AUTOSAR XML (schema 4-0-3)
standard types defined: Boolean, UInt32
package /AUTOSAR_Platform/DataConstrs
  range DC_Boolean: raw 0..1
package /PATAC/Facility/DataTypes/Implementation
  compu method COMPU_Boolean: 0=FALSE, 1=TRUE
  unit NoUnit: factor-si-to-unit=1, offset-si-to-unit=0
package /PATAC/MSM/ComponentTypes
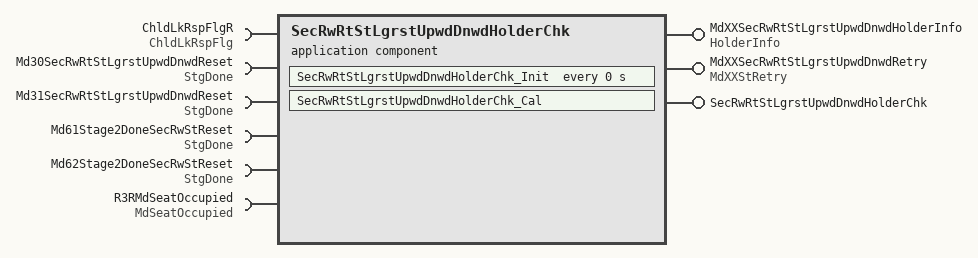
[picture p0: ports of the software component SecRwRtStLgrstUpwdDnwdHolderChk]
  application sw component type SecRwRtStLgrstUpwdDnwdHolderChk
    provide port MdXXSecRwRtStLgrstUpwdDnwdHolderInfo: nonqueued-sender-com-spec{data-element=HolderInfo/Val, init-value=0}, provided-interface=HolderInfo
    provide port MdXXSecRwRtStLgrstUpwdDnwdRetry: nonqueued-sender-com-spec{data-element=MdXXStRetry/Val, init-value=0}, provided-interface=MdXXStRetry
    provide port SecRwRtStLgrstUpwdDnwdHolderChk: server-com-spec{operation=Cal, queue-length=1}, provided-interface=SecRwRtStLgrstUpwdDnwdHolderChk
    6 x require port:
      ChldLkRspFlgR: nonqueued-receiver-com-spec{data-element=ChldLkRspFlg/Val, filter=data-filter-type=ALWAYS, init-value=0}, required-interface=ChldLkRspFlg
      Md30SecRwRtStLgrstUpwdDnwdReset: nonqueued-receiver-com-spec{data-element=StgDone/Val, filter=data-filter-type=ALWAYS, init-value=0}, required-interface=StgDone
      Md31SecRwRtStLgrstUpwdDnwdReset: nonqueued-receiver-com-spec{data-element=StgDone/Val, filter=data-filter-type=ALWAYS, init-value=0}, required-interface=StgDone
      Md61Stage2DoneSecRwStReset: nonqueued-receiver-com-spec{data-element=StgDone/Val, filter=data-filter-type=ALWAYS, init-value=0}, required-interface=StgDone
      Md62Stage2DoneSecRwStReset: nonqueued-receiver-com-spec{data-element=StgDone/Val, filter=data-filter-type=ALWAYS, init-value=0}, required-interface=StgDone
      R3RMdSeatOccupied: nonqueued-receiver-com-spec{data-element=MdSeatOccupied/Val, filter=data-filter-type=ALWAYS, init-value=0}, required-interface=MdSeatOccupied
    behavior SecRwRtStLgrstUpwdDnwdHolderChk_InternalBehavior
      operation invoked event OIT_SecRwRtStLgrstUpwdDnwdHolderChk_Cal_SecRwRtStLgrstUpwdDnwdHolderChk_Cal: start-on-event=SecRwRtStLgrstUpwdDnwdHolderChk_Cal, operation=SecRwRtStLgrstUpwdDnwdHolderChk.Cal
      timing event SecRwRtStLgrstUpwdDnwdHolderChk_InitEvent: start-on-event=SecRwRtStLgrstUpwdDnwdHolderChk_Init, period=0
      runnable SecRwRtStLgrstUpwdDnwdHolderChk_Cal
        data-receive-point-by-arguments:
          6 x access:
            REC_ChldLkRspFlgR_Val: accessed-variable=ChldLkRspFlgR.Val
            REC_Md30SecRwRtStLgrstUpwdDnwdReset_Val: accessed-variable=Md30SecRwRtStLgrstUpwdDnwdReset.Val
            REC_Md31SecRwRtStLgrstUpwdDnwdReset_Val: accessed-variable=Md31SecRwRtStLgrstUpwdDnwdReset.Val
            REC_Md61Stage2DoneSecRwStReset_Val: accessed-variable=Md61Stage2DoneSecRwStReset.Val
            REC_Md62Stage2DoneSecRwStReset_Val: accessed-variable=Md62Stage2DoneSecRwStReset.Val
            REC_R3RMdSeatOccupied_Val: accessed-variable=R3RMdSeatOccupied.Val
        data-send-points:
          access SEND_MdXXSecRwRtStLgrstUpwdDnwdHolderInfo_Val: accessed-variable=MdXXSecRwRtStLgrstUpwdDnwdHolderInfo.Val
          access SEND_MdXXSecRwRtStLgrstUpwdDnwdRetry_Val: accessed-variable=MdXXSecRwRtStLgrstUpwdDnwdRetry.Val
      runnable SecRwRtStLgrstUpwdDnwdHolderChk_Init
  swc implementation SecRwRtStLgrstUpwdDnwdHolderChk_Implementation: behavior=SecRwRtStLgrstUpwdDnwdHolderChk_InternalBehavior
    code-descriptors:
      code Default: artifact-descriptors=autosar-engineering-object={short-label=Default, category=SWSRC}
package /PATAC/MSM/ModeAdjust/PortInterface
  client server interface SecRwRtStLgrstUpwdDnwdHolderChk
    operation Cal
  5 x sender receiver interface:
    ChldLkRspFlg: invalidation-policy{data-element=ChldLkRspFlg/Val, handle-invalid=DONT-INVALIDATE}
      data Val: type=Boolean
    HolderInfo: invalidation-policy{data-element=HolderInfo/Val, handle-invalid=DONT-INVALIDATE}
      data Val: type=UInt32
    MdSeatOccupied: invalidation-policy{data-element=MdSeatOccupied/Val, handle-invalid=DONT-INVALIDATE}
      data Val: type=Boolean
    MdXXStRetry: invalidation-policy{data-element=MdXXStRetry/Val, handle-invalid=DONT-INVALIDATE}
      data Val: type=UInt32
    StgDone: invalidation-policy{data-element=StgDone/Val, handle-invalid=DONT-INVALIDATE}
      data Val: type=Boolean
